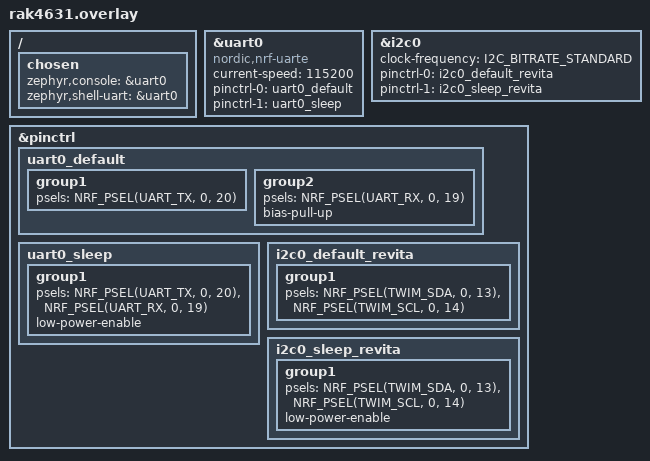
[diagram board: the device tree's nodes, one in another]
/*
 * Buzzer test - Tower
 * Console: uart0 (P0.20 TX / P0.19 RX) @ 115200 → ttyUSB1
 *
 * Buzzer 제어 (MCP23017 @ 0x20):
 *   GPA2 = 12_14V_EN  (HIGH = 12V 부스트 ON)
 *   GPB1 = BUZZER_EN  (HIGH = 부저 ON)
 *
 * I2C0: SDA=P0.13, SCL=P0.14, 100kHz (Standard mode)
 *
 * 참고: tower.h
 */

/ {
	chosen {
		zephyr,console = &uart0;
		zephyr,shell-uart = &uart0;
	};
};

&uart0 {
	compatible = "nordic,nrf-uarte";
	status = "okay";
	current-speed = <115200>;
	pinctrl-0 = <&uart0_default>;
	pinctrl-1 = <&uart0_sleep>;
	pinctrl-names = "default", "sleep";
};

&i2c0 {
	status = "okay";
	clock-frequency = <I2C_BITRATE_STANDARD>;
	pinctrl-0 = <&i2c0_default_revita>;
	pinctrl-1 = <&i2c0_sleep_revita>;
	pinctrl-names = "default", "sleep";
};

&pinctrl {
	uart0_default: uart0_default {
		group1 {
			psels = <NRF_PSEL(UART_TX, 0, 20)>;
		};
		group2 {
			psels = <NRF_PSEL(UART_RX, 0, 19)>;
			bias-pull-up;
		};
	};

	uart0_sleep: uart0_sleep {
		group1 {
			psels = <NRF_PSEL(UART_TX, 0, 20)>,
				<NRF_PSEL(UART_RX, 0, 19)>;
			low-power-enable;
		};
	};

	i2c0_default_revita: i2c0_default_revita {
		group1 {
			psels = <NRF_PSEL(TWIM_SDA, 0, 13)>,
				<NRF_PSEL(TWIM_SCL, 0, 14)>;
		};
	};

	i2c0_sleep_revita: i2c0_sleep_revita {
		group1 {
			psels = <NRF_PSEL(TWIM_SDA, 0, 13)>,
				<NRF_PSEL(TWIM_SCL, 0, 14)>;
			low-power-enable;
		};
	};
};
